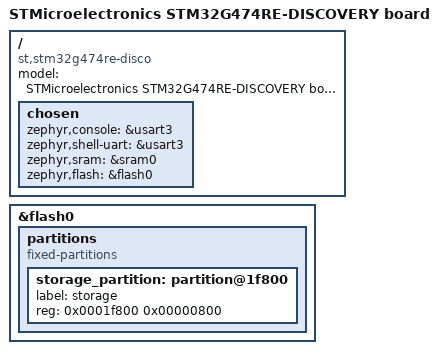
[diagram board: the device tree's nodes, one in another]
/*
 * Copyright (c) 2019 STMicroelectronics.
 *
 * SPDX-License-Identifier: Apache-2.0
 */

/dts-v1/;
#include <st/g4/stm32g473Xe.dtsi>
#include <st/g4/stm32g474r(b-c-e)tx-pinctrl.dtsi>
#include <stm32g473re_disco.dtsi>

/ {
	model = "STMicroelectronics STM32G474RE-DISCOVERY board";
	compatible = "st,stm32g474re-disco";

	chosen {
		zephyr,console = &usart3;
		zephyr,shell-uart = &usart3;
		zephyr,sram = &sram0;
		zephyr,flash = &flash0;
	};
};

&flash0 {
	/*
	 * For more information, see:
	 * http://docs.zephyrproject.org/latest/guides/dts/index.html#flash-partitions
	 */
	partitions {
		compatible = "fixed-partitions";
		#address-cells = <1>;
		#size-cells = <1>;

		/* Set 2Kb of storage at the end of the 128Kb of flash */
		storage_partition: partition@1f800 {
			label = "storage";
			reg = <0x0001f800 0x00000800>;
		};
	};
};

